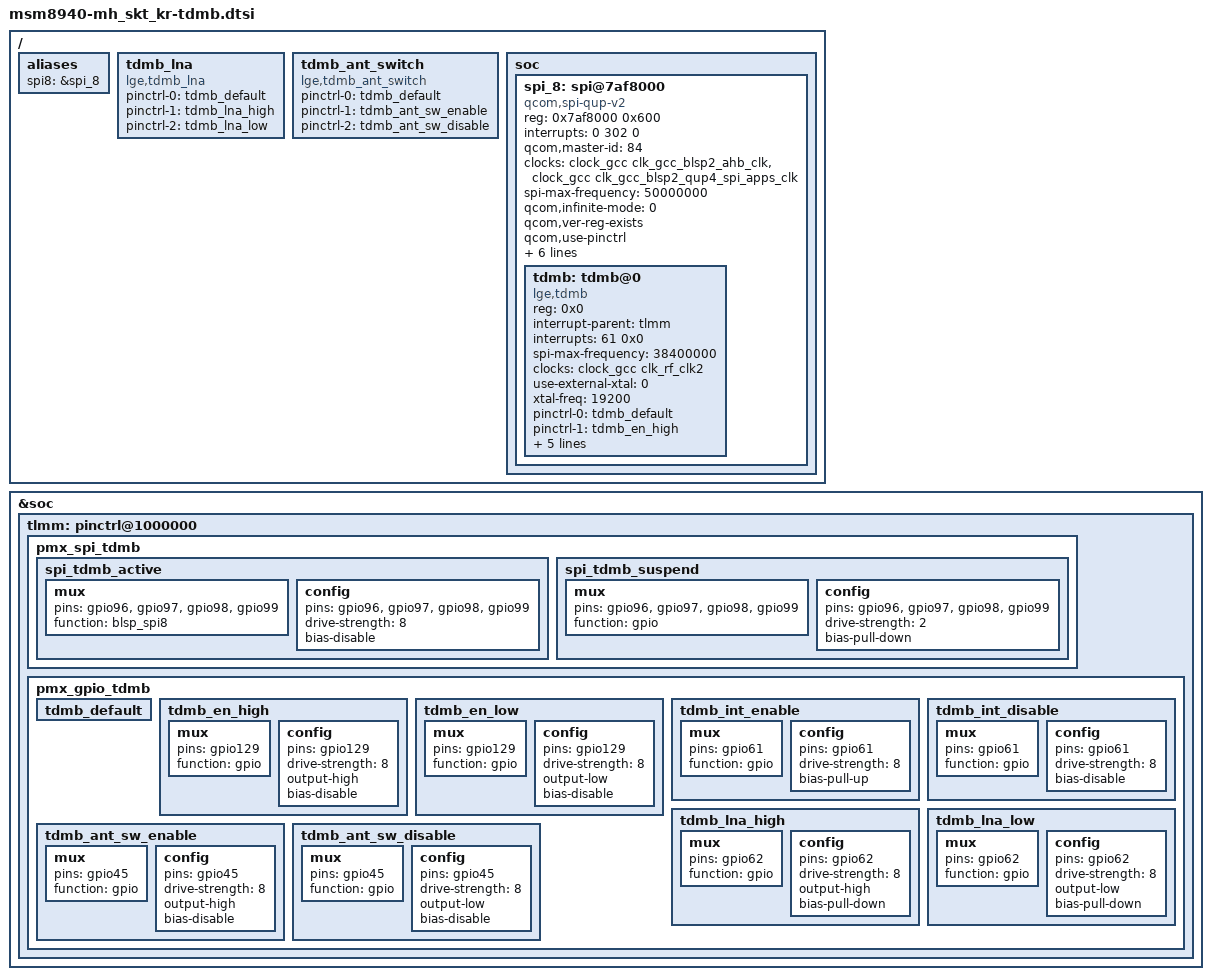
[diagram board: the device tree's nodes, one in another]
/* Copyright (c) 2014, The Linux Foundation. All rights reserved.
 *
 * This program is free software; you can redistribute it and/or modify
 * it under the terms of the GNU General Public License version 2 and
 * only version 2 as published by the Free Software Foundation.
 *
 * This program is distributed in the hope that it will be useful,
 * but WITHOUT ANY WARRANTY; without even the implied warranty of
 * MERCHANTABILITY or FITNESS FOR A PARTICULAR PURPOSE.  See the
 * GNU General Public License for more details.
 */

/ {
	aliases {
		spi8 = &spi_8;
	};

	tdmb_lna: tdmb_lna {
	compatible = "lge,tdmb_lna";
	status = "diasbled";
	};

	tdmb_ant_switch: tdmb_ant_switch {
	compatible = "lge,tdmb_ant_switch";
	status = "diasbled";
	};

	soc {
		spi_8: spi@7af8000{    /* BLSP-2 QUP3 */
		compatible = "qcom,spi-qup-v2";

		#address-cells = <1>;
		#size-cells = <0>;

		reg-names = "spi_physical"/*, "spi_bam_physical"*/;
		reg = <0x7af8000 0x600>/* , <0x7ac4000 0x1f000>*/;

		interrupt-names = "spi_irq";
		interrupts = <0 302 0>;

		qcom,master-id = <84>;

		clock-names = "iface_clk", "core_clk";
		clocks = <&clock_gcc clk_gcc_blsp2_ahb_clk>,
			<&clock_gcc clk_gcc_blsp2_qup4_spi_apps_clk>;

		spi-max-frequency = <50000000>;

		qcom,infinite-mode = <0>;
		qcom,ver-reg-exists;

		/* Assign runtime functions to pins */

		/*qcom,use-bam;*/
		/*qcom,bam-consumer-pipe-index = <10>;*/
		/*qcom,bam-producer-pipe-index = <11>;*/

		qcom,use-pinctrl;
		pinctrl-names = "spi_default", "spi_sleep";
		pinctrl-0 = <&spi_tdmb_active>;
		pinctrl-1 = <&spi_tdmb_suspend>;

		qcom,gpio-mosi = <&tlmm 96 0x00>;
		qcom,gpio-miso = <&tlmm 97 0x00>;
		qcom,gpio-cs0 = <&tlmm 98 0x00>;
		qcom,gpio-clk = <&tlmm 99 0x00>;

		status = "okay";
		};
	};
};

&spi_8 {
	tdmb: tdmb@0 {
		compatible = "lge,tdmb";
		status = "okay";
	};
};

&tdmb {
	reg = <0x0>;
	interrupt-parent = <&tlmm>;
	interrupts = <61 0x0>;

	spi-max-frequency = <38400000>;

	/* TDMB CLK */
	clock-names = "tdmb_xo";
	clocks = <&clock_gcc clk_rf_clk2>;

	/*set hw configure here
	when use pmic clk buffer, change use-xtal to 0, and set xtal-freq value*/
	use-external-xtal = <0>;
	xtal-freq = <19200>;

	pinctrl-names = "default",
			"en_high", "en_low",
			"irq_enable", "irq_disable";

	pinctrl-0 = <&tdmb_default>;
	pinctrl-1 = <&tdmb_en_high>;
	pinctrl-2 = <&tdmb_en_low>;
	pinctrl-3 = <&tdmb_int_enable>;
	pinctrl-4 = <&tdmb_int_disable>;

	tdmb-ldo-supply = <&pm8937_l5>;
	ant-sw-io-supply = <&pm8937_l10>;

	status = "okay";
};

&tdmb_lna {
	pinctrl-names = "default",
			"lna_high", "lna_low";

	pinctrl-0 = <&tdmb_default>;
	pinctrl-1 = <&tdmb_lna_high>;
	pinctrl-2 = <&tdmb_lna_low>;

	status = "okay";
};

&tdmb_ant_switch {
	pinctrl-names = "default",
			"ant_sw_enable", "ant_sw_disable";

	pinctrl-0 = <&tdmb_default>;
	pinctrl-1 = <&tdmb_ant_sw_enable>;
	pinctrl-2 = <&tdmb_ant_sw_disable>;

	status = "okay";
};

&soc {
	tlmm: pinctrl@1000000 {
		pmx_spi_tdmb {
			spi_tdmb_active: spi_tdmb_active {
				mux {
					pins =  "gpio96", "gpio97", "gpio98", "gpio99";
					function = "blsp_spi8";
				};
				config {
					pins =  "gpio96", "gpio97", "gpio98", "gpio99";
					drive-strength = <8>; /* 8MA */
					bias-disable;
				};
			};

			spi_tdmb_suspend: spi_tdmb_suspend {
				mux {
					pins =  "gpio96", "gpio97", "gpio98", "gpio99";
					function = "gpio";
				};
				config {
					pins =  "gpio96", "gpio97", "gpio98", "gpio99";
					drive-strength = <2>; /* 8MA */
					bias-pull-down;
				};
			};
		};

		pmx_gpio_tdmb {
			tdmb_default: tdmb_default {
			};

			tdmb_en_high: tdmb_en_high {
				mux {
					pins = "gpio129";
					function = "gpio";
				};
				config {
					pins = "gpio129";
					drive-strength = <8>; /* 8MA */
					output-high;
					bias-disable;
				};
			};

			tdmb_en_low: tdmb_en_low {
				mux {
					pins = "gpio129";
					function = "gpio";
				};
				config {
					pins = "gpio129";
					drive-strength = <8>; /* 8MA */
					output-low;
					bias-disable;
				};
			};

			tdmb_int_enable: tdmb_int_enable {
				mux {
					pins = "gpio61";
					function = "gpio";
				};
				config {
					pins = "gpio61";
					drive-strength = <8>; /* 8MA */
					bias-pull-up;
				};
			};

			tdmb_int_disable: tdmb_int_disable {
				mux {
					pins = "gpio61";
					function = "gpio";
				};
				config {
					pins = "gpio61";
					drive-strength = <8>; /* 8MA */
					bias-disable;
				};
			};

			tdmb_lna_high: tdmb_lna_high {
				mux {
					pins = "gpio62";
					function = "gpio";
				};
				config {
					pins = "gpio62";
					drive-strength = <8>; /* 8MA */
					output-high;
					bias-pull-down;
				};
			};

			tdmb_lna_low: tdmb_lna_low {
				mux {
					pins = "gpio62";
					function = "gpio";
				};
				config {
					pins = "gpio62";
					drive-strength = <8>; /* 8MA */
					output-low;
					bias-pull-down;
				};
			};

			tdmb_ant_sw_enable: tdmb_ant_sw_enable {
				mux {
					pins = "gpio45";
					function = "gpio";
				};
				config {
					pins = "gpio45";
					drive-strength = <8>; /* 8MA */
					output-high;
					bias-disable;
				};
			};

			tdmb_ant_sw_disable: tdmb_ant_sw_disable {
				mux {
					pins = "gpio45";
					function = "gpio";
				};
				config {
					pins = "gpio45";
					drive-strength = <8>; /* 8MA */
					output-low;
					bias-disable;
				};
			};
		};
	};
};
